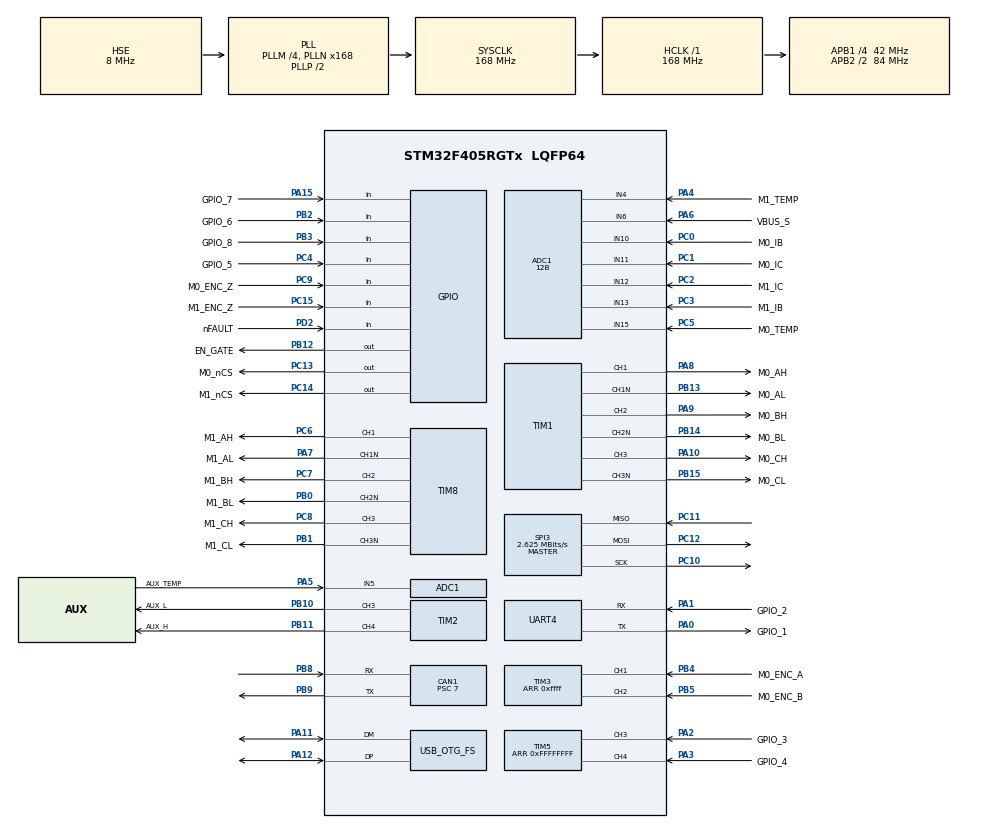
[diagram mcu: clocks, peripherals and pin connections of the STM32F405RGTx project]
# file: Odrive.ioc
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NVIC.CAN1_RX1_IRQn=true\:6\:0\:true\:false\:true\:true\:true\:true
PH0-OSC_IN.Signal=RCC_OSC_IN
SPI3.Direction=SPI_DIRECTION_2LINES
SPI3.VirtualType=VM_MASTER
ADC3.ExternalTrigInjecConv=ADC_EXTERNALTRIGINJECCONV_T1_TRGO
ADC3.ExternalTrigInjecConvEdge=ADC_EXTERNALTRIGINJECCONVEDGE_RISING
PC12.Signal=SPI3_MOSI
USB_DEVICE.PID_CDC_FS=0x0D32
PB14.GPIO_Label=M0_BL
PC6.GPIO_Label=M1_AH
Dma.SPI3_RX.2.Direction=DMA_PERIPH_TO_MEMORY
ADC2.InjectedOffset-1\#ChannelInjectedConversion=0
PA6.GPIO_Label=VBUS_S
PB6.GPIO_Label=M1_SCL
PB13.Signal=TIM1_CH1N
PC15-OSC32_OUT.GPIO_Label=M1_ENC_Z
TIM8.OffStateIDLEMode=TIM_OSSI_ENABLE
RCC.SYSCLKSource=RCC_SYSCLKSOURCE_PLLCLK
USB_OTG_FS.vbus_sensing_enable=DISABLE
ADC3.Rank-7\#ChannelRegularConversion=1
NVIC.TIM5_IRQn=true\:5\:0\:false\:false\:true\:true\:true\:true
NVIC.CAN1_TX_IRQn=true\:6\:0\:true\:false\:true\:true\:true\:true
RCC.APB2TimFreq_Value=84000000
PB6.Signal=I2C1_SCL
Dma.ADC1.0.Direction=DMA_PERIPH_TO_MEMORY
PC7.Signal=S_TIM8_CH2
ADC1.InjNumberOfConversion=1
PC3.Signal=ADCx_IN13
ADC3.ScanConvMode=DISABLE
ADC2.EOCSelection=ADC_EOC_SINGLE_CONV
PA1.GPIO_PuPd=GPIO_NOPULL
Dma.ADC1.0.MemDataAlignment=DMA_MDATAALIGN_HALFWORD
NVIC.TIM8_TRG_COM_TIM14_IRQn=true\:0\:0\:false\:false\:true\:false\:false\:true
PB2.Signal=GPIO_Input
ADC1.ScanConvMode=DISABLE
TIM2.OCMode_PWM-PWM\ Generation3\ CH3=TIM_OCMODE_PWM2
PC13-ANTI_TAMP.Signal=GPIO_Output
SH.ADCx_IN15.1=ADC2_IN15,IN15
SH.ADCx_IN15.0=ADC1_IN15,IN15
PB12.GPIO_Label=EN_GATE
ADC3.ExternalTrigConv=ADC_EXTERNALTRIGCONV_T8_TRGO
ADC3.InjectedConvMode=None
PC4.GPIO_Label=GPIO_5
USB_DEVICE.MANUFACTURER_STRING-CDC_FS=ODrive Robotics
PB14.Mode=PWM Generation2 CH2 CH2N
PB9.Stacked=true
PB1.GPIO_Label=M1_CL
Dma.ADC1.0.PeriphInc=DMA_PINC_DISABLE
TIM1.DeadTime=TIM_1_8_DEADTIME_CLOCKS
ADC3.ContinuousConvMode=DISABLE
TIM1.OCMode_PWM-PWM\ Generation1\ CH1\ CH1N=TIM_OCMODE_PWM2
ADC2.EnableAnalogWatchDog=false
PA8.Signal=S_TIM1_CH1
ADC1.InjectedConvMode=None
USB_DEVICE.VID-CDC_FS=0x1209
VP_SYS_VS_tim14.Mode=TIM14
VP_TIM1_VS_ClockSourceINT.Mode=Internal
ADC1.SamplingTime-0\#ChannelRegularConversion=ADC_SAMPLETIME_3CYCLES
CAN1.Prescaler=7
Mcu.Package=LQFP64
PB9.Signal=CAN1_TX
PB1.Signal=TIM8_CH3N
NVIC.TimeBase=TIM8_TRG_COM_TIM14_IRQn
SPI3.Mode=SPI_MODE_MASTER
NVIC.TimeBaseIP=TIM14
TIM1.OCMode_PWM-PWM\ Generation3\ CH3\ CH3N=TIM_OCMODE_PWM2
PA10.Signal=S_TIM1_CH3
PC11.Mode=Full_Duplex_Master
Dma.SPI3_RX.2.PeriphInc=DMA_PINC_DISABLE
ADC1.Rank-1\#ChannelInjectedConversion=1
ADC3.DMAContinuousRequests=DISABLE
RCC.APB2CLKDivider=RCC_HCLK_DIV2
ADC3.ExternalTrigConvEdge=ADC_EXTERNALTRIGCONVEDGE_RISING
RCC.APB1TimFreq_Value=84000000
TIM5.ICFilter_CH4=15
TIM5.ICFilter_CH3=15
Dma.ADC1.0.FIFOMode=DMA_FIFOMODE_DISABLE
TIM1.OCMode_PWM-PWM\ Generation2\ CH2\ CH2N=TIM_OCMODE_PWM2
TIM1.Period=TIM_1_8_PERIOD_CLOCKS
PB13.Mode=PWM Generation1 CH1 CH1N
ADC2.ExternalTrigInjecConvEdge=ADC_EXTERNALTRIGINJECCONVEDGE_RISING
CAN1.CalculateTimeBit=500
TIM2.OCMode_PWM-PWM\ Generation4\ CH4=TIM_OCMODE_PWM2
PA4.GPIO_Label=M1_TEMP
ADC1.EOCSelection=ADC_EOC_SINGLE_CONV
ADC2.ScanConvMode=DISABLE
CAN1.CalculateTimeQuantum=166.66666666666669
NVIC.UART4_IRQn=true\:5\:0\:false\:false\:true\:true\:true\:true
SH.S_TIM8_CH3.0=TIM8_CH3,PWM Generation3 CH3 CH3N
Dma.SPI3_TX.1.MemInc=DMA_MINC_ENABLE
TIM8.OffStateRunMode=TIM_OSSR_ENABLE
Dma.ADC1.0.Instance=DMA2_Stream0
FREERTOS.Tasks01=defaultTask,0,256,StartDefaultTask,Default,NULL,Dynamic,NULL,NULL
ADC1.Rank-0\#ChannelRegularConversion=1
PD2.GPIO_PuPd=GPIO_PULLUP
TIM5.Channel-Input_Capture4_from_TI4=TIM_CHANNEL_4
SH.ADCx_IN6.0=ADC1_IN6,IN6
PC13-ANTI_TAMP.GPIO_Label=M0_nCS
SH.ADCx_IN6.1=ADC2_IN6,IN6
TIM1.CounterMode=TIM_COUNTERMODE_CENTERALIGNED3
PA9.GPIO_Label=M0_BH
TIM8.Channel-Output\ Compare4\ No\ Output=TIM_CHANNEL_4
FREERTOS.INCLUDE_vTaskDelayUntil=1
FREERTOS.configCHECK_FOR_STACK_OVERFLOW=1
PC6.Signal=S_TIM8_CH1
PC2.Signal=ADCx_IN12
PB11.GPIO_Label=AUX_H
TIM1.Channel-PWM\ Generation1\ CH1\ CH1N=TIM_CHANNEL_1
ADC2.Channel-1\#ChannelInjectedConversion=ADC_CHANNEL_10
Dma.SPI3_TX.1.Priority=DMA_PRIORITY_MEDIUM
TIM2.OCPolarity_3=TIM_OCPOLARITY_LOW
ADC1.ExternalTrigConvEdge=ADC_EXTERNALTRIGCONVEDGE_NONE
PC0.Signal=ADCx_IN10
RCC.APB1CLKDivider=RCC_HCLK_DIV4
UART4.VirtualMode=Asynchronous
PC14-OSC32_IN.Signal=GPIO_Output
SH.S_TIM8_CH2.0=TIM8_CH2,PWM Generation2 CH2 CH2N
PC13-ANTI_TAMP.PinState=GPIO_PIN_SET
ADC3.Resolution=ADC_RESOLUTION_12B
PA0-WKUP.GPIO_Label=GPIO_1
PA0-WKUP.Signal=SharedStack_PA0
TIM1.Channel-PWM\ Generation2\ CH2\ CH2N=TIM_CHANNEL_2
PA8.GPIO_Label=M0_AH
ADC2.ContinuousConvMode=DISABLE
TIM3.IC2Filter=4
USB_DEVICE.PRODUCT_STRING_CDC_FS=ODrive v3.3
USB_DEVICE.APP_TX_DATA_SIZE-CDC_FS=64
Dma.ADC1.0.Priority=DMA_PRIORITY_LOW
PA9.Signal=S_TIM1_CH2
Dma.SPI3_TX.1.MemDataAlignment=DMA_MDATAALIGN_HALFWORD
TIM1.Channel-PWM\ Generation3\ CH3\ CH3N=TIM_CHANNEL_3
ADC1.Channel-1\#ChannelInjectedConversion=ADC_CHANNEL_6
ADC3.NbrOfConversion=1
SPI3.FirstBit=SPI_FIRSTBIT_MSB
PB10.Signal=S_TIM2_CH3
PB14.Signal=TIM1_CH2N
PA5.Signal=ADCx_IN5
TIM3.IC1Filter=4
SH.S_TIM8_CH1.0=TIM8_CH1,PWM Generation1 CH1 CH1N
PC12.Mode=Full_Duplex_Master
ADC3.SamplingTime-8\#ChannelInjectedConversion=ADC_SAMPLETIME_3CYCLES
TIM13.Period=(2 * TIM_1_8_PERIOD_CLOCKS * (TIM_1_8_RCR+1)) * (TIM_APB1_CLOCK_HZ / TIM_1_8_CLOCK_HZ)
TIM1.TIM_MasterOutputTrigger=TIM_TRGO_UPDATE
VP_TIM13_VS_ClockSourceINT.Mode=Enable_Timer
PB4.GPIO_Label=M0_ENC_A
PB15.GPIO_Label=M0_CL
ADC1.InjectedOffset-1\#ChannelInjectedConversion=0
SH.ADCx_IN4.1=ADC2_IN4,IN4
PA1.GPIO_Label=GPIO_2
SH.ADCx_IN4.0=ADC1_IN4,IN4
ADC1.DMAContinuousRequests=DISABLE
TIM2.Period=TIM_APB1_PERIOD_CLOCKS
PA13.Mode=Serial_Wire
TIM8.RepetitionCounter=TIM_1_8_RCR
ADC2.Resolution=ADC_RESOLUTION_12B
ADC1.ExternalTrigConv=ADC_SOFTWARE_START
TIM8.Period=TIM_1_8_PERIOD_CLOCKS
PC7.GPIO_Label=M1_BH
RCC.APB2TimCLKDivider=1
Dma.SPI3_TX.1.PeriphInc=DMA_PINC_DISABLE
PA4.Signal=ADCx_IN4
PB5.Signal=S_TIM3_CH2
ADC1.master=1
PA5.GPIO_Label=AUX_TEMP
ADC2.NbrOfConversionFlag=1
TIM8.TIM_MasterOutputTrigger=TIM_TRGO_UPDATE
PA11.Signal=USB_OTG_FS_DM
ProjectManager.HeapSize=0x3C00
PB1.Mode=PWM Generation3 CH3 CH3N
ADC3.EOCSelection=ADC_EOC_SINGLE_CONV
NVIC.TIM1_UP_TIM10_IRQn=true\:0\:0\:false\:false\:false\:false\:true\:true
NVIC.TIM8_UP_TIM13_IRQn=true\:0\:0\:false\:false\:false\:false\:true\:true
SH.ADCx_IN5.0=ADC1_IN5,IN5
SH.ADCx_IN5.1=ADC2_IN5,IN5
NVIC.PriorityGroup=NVIC_PRIORITYGROUP_4
PB8.Mode=Master
PC3.GPIO_Label=M1_IB
PA0-WKUP.GPIO_PuPd=GPIO_PULLDOWN
TIM2.Pulse-PWM\ Generation4\ CH4=TIM_APB1_PERIOD_CLOCKS+1
ADC3.Rank-8\#ChannelInjectedConversion=1
PD2.Signal=GPIO_Input
PB0.Signal=TIM8_CH2N
PC1.Signal=ADCx_IN11
PD2.GPIO_Label=nFAULT
NVIC.CAN1_RX0_IRQn=true\:6\:0\:true\:false\:true\:true\:true\:true
TIM8.CounterMode=TIM_COUNTERMODE_CENTERALIGNED3
ADC3.EnableAnalogWatchDog=false
Mcu.Family=STM32F4
ADC2.ExternalTrigConv=ADC_EXTERNALTRIGCONV_T8_TRGO
USB_DEVICE.CLASS_NAME_FS=CDC
RCC.CortexFreq_Value=168000000
CAN1.AutoWakeUp=ENABLE
ADC1.ContinuousConvMode=DISABLE
ADC2.Channel-0\#ChannelRegularConversion=ADC_CHANNEL_13
TIM1.RepetitionCounter=TIM_1_8_RCR
ADC3.SamplingTime-7\#ChannelRegularConversion=ADC_SAMPLETIME_3CYCLES
ADC2.InjectedConvMode=None
Dma.SPI3_RX.2.Instance=DMA1_Stream0
PC10.Signal=SPI3_SCK
TIM3.EncoderMode=TIM_ENCODERMODE_TI12
PC0.GPIO_Label=M0_IB
PA11.Mode=Device_Only
PB0.GPIO_Label=M1_BL
USB_DEVICE.VirtualMode-CDC_FS=Cdc
PB13.GPIO_Label=M0_AL
PB11.Signal=S_TIM2_CH4
PB15.Signal=TIM1_CH3N
ADC2.DiscontinuousConvMode=DISABLE
Dma.SPI3_RX.2.PeriphDataAlignment=DMA_PDATAALIGN_HALFWORD
ProjectManager.StackSize=0x800
NVIC.ADC_IRQn=true\:5\:0\:false\:false\:true\:true\:true\:true
PA15.GPIO_Label=GPIO_7
PA12.Signal=USB_OTG_FS_DP
Mcu.UserConstants=TIM_1_8_CLOCK_HZ,168000000;TIM_1_8_PERIOD_CLOCKS,3500;TIM_1_8_DEADTIME_CLOCKS,20;TIM_APB1_CLOCK_HZ,84000000;TIM_APB1_PERIOD_CLOCKS,4096;TIM_APB1_DEADTIME_CLOCKS,40;TIM_1_8_RCR,2
ADC2.DMAContinuousRequests=DISABLE
ADC2.Rank-1\#ChannelInjectedConversion=1
TIM8.Channel-PWM\ Generation2\ CH2\ CH2N=TIM_CHANNEL_2
RCC.HCLKFreq_Value=168000000
ADC1.Resolution=ADC_RESOLUTION_12B
USB_DEVICE.SERIALNUMBER_STRING_CDC_FS=000000000001
TIM3.Period=0xffff
SH.S_TIM5_CH3.0=TIM5_CH3,Input_Capture3_from_TI3
ADC3.InjectedOffset-8\#ChannelInjectedConversion=0
NVIC.DMA2_Stream0_IRQn=true\:5\:0\:false\:false\:false\:true\:false\:true
NVIC.CAN1_SCE_IRQn=true\:6\:0\:true\:false\:true\:true\:true\:true
PB8.Stacked=true
RCC.AHBFreq_Value=168000000
PH0-OSC_IN.Mode=HSE-External-Oscillator
SPI3.DataSize=SPI_DATASIZE_16BIT
TIM8.Channel-PWM\ Generation1\ CH1\ CH1N=TIM_CHANNEL_1
ADC1.Channel-0\#ChannelRegularConversion=ADC_CHANNEL_6
ADC1.ExternalTrigInjecConv=ADC_EXTERNALTRIGINJECCONV_T1_TRGO
RCC.HSE_VALUE=8000000
ADC3.InjNumberOfConversion=1
PA14.Mode=Serial_Wire
PA0-WKUP.Stacked=true
PA10.GPIO_Label=M0_CH
ADC3.DataAlign=ADC_DATAALIGN_RIGHT
PB7.Signal=I2C1_SDA
SH.S_TIM3_CH1.0=TIM3_CH1,Encoder_Interface
PA1.Stacked=true
FREERTOS.configTOTAL_HEAP_SIZE=65536
Dma.SPI3_RX.2.FIFOMode=DMA_FIFOMODE_DISABLE
SH.SharedStack_PA1.0=GPIO_Input+0
VP_FREERTOS_VS_ENABLE.Mode=Enabled
USB_DEVICE.APP_RX_DATA_SIZE-CDC_FS=64
SH.SharedStack_PA1.1=UART4_RX,Asynchronous
PH1-OSC_OUT.Mode=HSE-External-Oscillator
PB7.GPIO_Label=M1_SDA
TIM8.OCMode_PWM-PWM\ Generation1\ CH1\ CH1N=TIM_OCMODE_PWM2
PA6.Signal=ADCx_IN6
TIM8.Channel-PWM\ Generation3\ CH3\ CH3N=TIM_CHANNEL_3
PC14-OSC32_IN.PinState=GPIO_PIN_SET
ADC1.SamplingTime-1\#ChannelInjectedConversion=ADC_SAMPLETIME_3CYCLES
NVIC.OTG_FS_IRQn=true\:5\:0\:false\:false\:true\:true\:true\:true
PA2.GPIO_Label=GPIO_3
USB_OTG_FS.VirtualMode=Device_Only
PA15.Signal=GPIO_Input
TIM8.OCMode_PWM-PWM\ Generation3\ CH3\ CH3N=TIM_OCMODE_PWM2
ADC2.SamplingTime-0\#ChannelRegularConversion=ADC_SAMPLETIME_3CYCLES
NVIC.SPI3_IRQn=true\:5\:0\:false\:false\:true\:true\:true\:true
ADC3.ClockPrescaler=ADC_CLOCK_SYNC_PCLK_DIV4
Dma.SPI3_TX.1.Direction=DMA_MEMORY_TO_PERIPH
PB5.GPIO_Label=M0_ENC_B
Dma.SPI3_RX.2.Priority=DMA_PRIORITY_MEDIUM
ADC2.NbrOfConversion=1
Dma.Request2=SPI3_RX
Dma.Request1=SPI3_TX
NVIC.DMA1_Stream0_IRQn=true\:5\:0\:false\:false\:true\:true\:false\:true
PC14-OSC32_IN.GPIO_Label=M1_nCS
PC5.Signal=ADCx_IN15
ADC2.Rank-0\#ChannelRegularConversion=1
TIM8.OCMode_PWM-PWM\ Generation2\ CH2\ CH2N=TIM_OCMODE_PWM2
Dma.Request0=ADC1
PC2.GPIO_Label=M1_IC
SH.SharedStack_PA0.1=UART4_TX,Asynchronous
SH.SharedStack_PA0.0=GPIO_EXTI0+0
PB4.Signal=S_TIM3_CH1
PA3.Signal=S_TIM5_CH4
ADC1.ExternalTrigInjecConvEdge=ADC_EXTERNALTRIGINJECCONVEDGE_RISING
PB3.GPIO_Label=GPIO_8
ADC3.Channel-7\#ChannelRegularConversion=ADC_CHANNEL_12
SH.ADCx_IN13.2=ADC3_IN13,IN13
ADC2.ClockPrescaler=ADC_CLOCK_SYNC_PCLK_DIV4
SH.ADCx_IN13.1=ADC2_IN13,IN13
ADC3.DiscontinuousConvMode=DISABLE
TIM2.Channel-PWM\ Generation4\ CH4=TIM_CHANNEL_4
SH.ADCx_IN13.0=ADC1_IN13,IN13
ADC2.ExternalTrigInjecConv=ADC_EXTERNALTRIGINJECCONV_T1_TRGO
TIM1.OffStateIDLEMode=TIM_OSSI_ENABLE
PA7.Mode=PWM Generation1 CH1 CH1N
TIM2.CounterMode=TIM_COUNTERMODE_CENTERALIGNED3
PC9.GPIO_Label=M0_ENC_Z
USB_DEVICE.VirtualModeFS=Cdc_FS
ADC3.Channel-8\#ChannelInjectedConversion=ADC_CHANNEL_11
PC11.Signal=SPI3_MISO
PC8.Signal=S_TIM8_CH3
PC4.Signal=GPIO_Input
PC10.Mode=Full_Duplex_Master
ADC1.DiscontinuousConvMode=DISABLE
Dma.SPI3_TX.1.FIFOMode=DMA_FIFOMODE_DISABLE
Dma.SPI3_TX.1.Instance=DMA1_Stream5
TIM5.ICPolarity_CH4=TIM_INPUTCHANNELPOLARITY_BOTHEDGE
TIM5.ICPolarity_CH3=TIM_INPUTCHANNELPOLARITY_BOTHEDGE
FREERTOS.INCLUDE_uxTaskGetStackHighWaterMark=1
SH.ADCx_IN12.2=ADC3_IN12,IN12
PC8.GPIO_Label=M1_CH
Dma.SPI3_TX.1.PeriphDataAlignment=DMA_PDATAALIGN_HALFWORD
PA13.Signal=SYS_JTMS-SWDIO
FREERTOS.configUSE_IDLE_HOOK=1
SH.ADCx_IN12.1=ADC2_IN12,IN12
Dma.ADC1.0.PeriphDataAlignment=DMA_PDATAALIGN_HALFWORD
SH.ADCx_IN12.0=ADC1_IN12,IN12
SH.S_TIM1_CH1.0=TIM1_CH1,PWM Generation1 CH1 CH1N
CAN1.BS2=CAN_BS2_5TQ
CAN1.BS1=CAN_BS1_6TQ
Dma.SPI3_TX.1.Mode=DMA_NORMAL
ProjectManager.TargetToolchain=Makefile
PB10.GPIO_Label=AUX_L
NVIC.DMA1_Stream5_IRQn=true\:5\:0\:false\:false\:true\:true\:false\:true
Dma.ADC1.0.Mode=DMA_CIRCULAR
VP_USB_DEVICE_VS_USB_DEVICE_CDC_FS.Mode=CDC_FS
PB9.Mode=Master
RCC.LSE_VALUE=32768
PC15-OSC32_OUT.Signal=GPIO_Input
PA1.Signal=SharedStack_PA1
TIM3.IC2Polarity=TIM_ICPOLARITY_RISING
SH.S_TIM3_CH2.0=TIM3_CH2,Encoder_Interface
ADC2.SamplingTime-1\#ChannelInjectedConversion=ADC_SAMPLETIME_3CYCLES
PB0.Mode=PWM Generation2 CH2 CH2N
TIM8.DeadTime=TIM_1_8_DEADTIME_CLOCKS
board=Odrive
SPI3.CLKPhase=SPI_PHASE_2EDGE
RCC.VCOOutputFreq_Value=336000000
TIM1.OCNPolarity_1=TIM_OCNPOLARITY_HIGH
PB15.Mode=PWM Generation3 CH3 CH3N
VP_TIM1_VS_no_output4.Mode=Output Compare4 No Output
ADC1.EnableAnalogWatchDog=false
ADC2.DataAlign=ADC_DATAALIGN_RIGHT
RCC.APB2Freq_Value=84000000
SH.ADCx_IN11.2=ADC3_IN11,IN11
SPI3.CalculateBaudRate=2.625 MBits/s
TIM1.OCNPolarity_3=TIM_OCNPOLARITY_HIGH
SH.ADCx_IN11.1=ADC2_IN11,IN11
TIM1.OCNPolarity_2=TIM_OCNPOLARITY_HIGH
SH.ADCx_IN11.0=ADC1_IN11,IN11
SH.S_TIM1_CH2.0=TIM1_CH2,PWM Generation2 CH2 CH2N
SH.S_TIM2_CH3.0=TIM2_CH3,PWM Generation3 CH3
SPI3.BaudRatePrescaler=SPI_BAUDRATEPRESCALER_16
PC1.GPIO_Label=M0_IC
TIM2.Channel-PWM\ Generation3\ CH3=TIM_CHANNEL_3
PH1-OSC_OUT.Signal=RCC_OSC_OUT
CAN1.TimeSeg1=CAN_BS1_6TQ
SH.S_TIM5_CH4.0=TIM5_CH4,Input_Capture4_from_TI4
CAN1.TimeSeg2=CAN_BS2_5TQ
TIM1.OffStateRunMode=TIM_OSSR_ENABLE
ADC1.NbrOfConversion=1
Dma.SPI3_RX.2.Mode=DMA_NORMAL
Mcu.Name=STM32F405RGTx
PA2.Signal=S_TIM5_CH3
RCC.48MHZClocksFreq_Value=48000000
PB3.Signal=GPIO_Input
RCC.SYSCLKFreq_VALUE=168000000
PA7.GPIO_Label=M1_AL
PA12.Mode=Device_Only
PC5.GPIO_Label=M0_TEMP
Dma.SPI3_RX.2.MemInc=DMA_MINC_ENABLE
TIM3.IC1Polarity=TIM_ICPOLARITY_RISING
SH.ADCx_IN10.2=ADC3_IN10,IN10
SH.ADCx_IN10.1=ADC2_IN10,IN10
PA14.Signal=SYS_JTCK-SWCLK
Dma.ADC1.0.MemInc=DMA_MINC_ENABLE
SH.ADCx_IN10.0=ADC1_IN10,IN10
PB2.GPIO_Label=GPIO_6
SH.S_TIM2_CH4.0=TIM2_CH4,PWM Generation4 CH4
SH.S_TIM1_CH3.0=TIM1_CH3,PWM Generation3 CH3 CH3N
TIM1.Channel-Output\ Compare4\ No\ Output=TIM_CHANNEL_4
RCC.HSI_VALUE=16000000
ADC2.ExternalTrigConvEdge=ADC_EXTERNALTRIGCONVEDGE_RISING
RCC.PLLQ=7
ADC1.NbrOfConversionFlag=1
RCC.PLLM=4
RCC.PLLN=168
PB8.Signal=CAN1_RX
TIM5.Period=0xFFFFFFFF
PC9.Signal=GPIO_Input
Dma.SPI3_RX.2.MemDataAlignment=DMA_MDATAALIGN_HALFWORD
ADC1.DataAlign=ADC_DATAALIGN_RIGHT
RCC.APB1Freq_Value=42000000
ADC3.NbrOfConversionFlag=1
ADC1.ClockPrescaler=ADC_CLOCK_SYNC_PCLK_DIV4
ADC2.InjNumberOfConversion=1
PB12.Signal=GPIO_Output
TIM5.Channel-Input_Capture3_from_TI3=TIM_CHANNEL_3
PA3.GPIO_Label=GPIO_4
PA7.Signal=TIM8_CH1N

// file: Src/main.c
/**
  ******************************************************************************
  * @file           : main.c
  * @brief          : Main program body
  ******************************************************************************
  * This notice applies to any and all portions of this file
  * that are not between comment pairs USER CODE BEGIN and
  * USER CODE END. Other portions of this file, whether
  * inserted by the user or by software development tools
  * are owned by their respective copyright owners.
  *
  * Copyright (c) 2020 STMicroelectronics International N.V.
  * All rights reserved.
  *
  * Redistribution and use in source and binary forms, with or without
  * modification, are permitted, provided that the following conditions are met:
  *
  * 1. Redistribution of source code must retain the above copyright notice,
  *    this list of conditions and the following disclaimer.
  * 2. Redistributions in binary form must reproduce the above copyright notice,
  *    this list of conditions and the following disclaimer in the documentation
  *    and/or other materials provided with the distribution.
  * 3. Neither the name of STMicroelectronics nor the names of other
  *    contributors to this software may be used to endorse or promote products
  *    derived from this software without specific written permission.
  * 4. This software, including modifications and/or derivative works of this
  *    software, must execute solely and exclusively on microcontroller or
  *    microprocessor devices manufactured by or for STMicroelectronics.
  * 5. Redistribution and use of this software other than as permitted under
  *    this license is void and will automatically terminate your rights under
  *    this license.
  *
  * THIS SOFTWARE IS PROVIDED BY STMICROELECTRONICS AND CONTRIBUTORS "AS IS"
  * AND ANY EXPRESS, IMPLIED OR STATUTORY WARRANTIES, INCLUDING, BUT NOT
  * LIMITED TO, THE IMPLIED WARRANTIES OF MERCHANTABILITY, FITNESS FOR A
  * PARTICULAR PURPOSE AND NON-INFRINGEMENT OF THIRD PARTY INTELLECTUAL PROPERTY
  * RIGHTS ARE DISCLAIMED TO THE FULLEST EXTENT PERMITTED BY LAW. IN NO EVENT
  * SHALL STMICROELECTRONICS OR CONTRIBUTORS BE LIABLE FOR ANY DIRECT, INDIRECT,
  * INCIDENTAL, SPECIAL, EXEMPLARY, OR CONSEQUENTIAL DAMAGES (INCLUDING, BUT NOT
  * LIMITED TO, PROCUREMENT OF SUBSTITUTE GOODS OR SERVICES; LOSS OF USE, DATA,
  * OR PROFITS; OR BUSINESS INTERRUPTION) HOWEVER CAUSED AND ON ANY THEORY OF
  * LIABILITY, WHETHER IN CONTRACT, STRICT LIABILITY, OR TORT (INCLUDING
  * NEGLIGENCE OR OTHERWISE) ARISING IN ANY WAY OUT OF THE USE OF THIS SOFTWARE,
  * EVEN IF ADVISED OF THE POSSIBILITY OF SUCH DAMAGE.
  *
  ******************************************************************************
  */
#include "main.h"
#include "stm32f4xx_hal.h"
#include "cmsis_os.h"
#include "adc.h"
#include "can.h"
#include "dma.h"
#include "spi.h"
#include "tim.h"
#include "usart.h"
#include "usb_device.h"
#include "gpio.h"

/* USER CODE BEGIN PV */
/* Private variables ---------------------------------------------------------*/

/* USER CODE END PV */

void SystemClock_Config(void);
void MX_FREERTOS_Init(void);

/* USER CODE BEGIN PFP */
/* Private function prototypes -----------------------------------------------*/

/* USER CODE END PFP */

int main(void)
{

  /* MCU Configuration----------------------------------------------------------*/

  /* Reset of all peripherals, Initializes the Flash interface and the Systick. */
  HAL_Init();

  /* Configure the system clock */
  SystemClock_Config();

  /* Initialize all configured peripherals */
  MX_GPIO_Init();
  MX_DMA_Init();
  MX_ADC1_Init();
  MX_ADC2_Init();
  MX_CAN1_Init();
  MX_TIM1_Init();
  MX_TIM8_Init();
  MX_TIM3_Init();
  MX_SPI3_Init();
  MX_ADC3_Init();
  MX_TIM2_Init();
  MX_UART4_Init();
  MX_TIM5_Init();
  MX_TIM13_Init();

  /* Call init function for freertos objects (in freertos.c) */
  MX_FREERTOS_Init();

  /* Start scheduler */
  osKernelStart();

  /* We should never get here as control is now taken by the scheduler */

  /* Infinite loop */
  while (1)
  {

  }

}

void SystemClock_Config(void)
{

  RCC_OscInitTypeDef RCC_OscInitStruct;
  RCC_ClkInitTypeDef RCC_ClkInitStruct;

    /**Configure the main internal regulator output voltage
    */
  __HAL_RCC_PWR_CLK_ENABLE();

  __HAL_PWR_VOLTAGESCALING_CONFIG(PWR_REGULATOR_VOLTAGE_SCALE1);

    /**Initializes the CPU, AHB and APB busses clocks
    */
  RCC_OscInitStruct.OscillatorType = RCC_OSCILLATORTYPE_LSI|RCC_OSCILLATORTYPE_HSE;
  RCC_OscInitStruct.HSEState = RCC_HSE_ON;
  RCC_OscInitStruct.LSIState = RCC_LSI_ON;
  RCC_OscInitStruct.PLL.PLLState = RCC_PLL_ON;
  RCC_OscInitStruct.PLL.PLLSource = RCC_PLLSOURCE_HSE;
  RCC_OscInitStruct.PLL.PLLM = 4;
  RCC_OscInitStruct.PLL.PLLN = 168;
  RCC_OscInitStruct.PLL.PLLP = RCC_PLLP_DIV2;
  RCC_OscInitStruct.PLL.PLLQ = 7;
  if (HAL_RCC_OscConfig(&RCC_OscInitStruct) != HAL_OK)
  {
    _Error_Handler(__FILE__, __LINE__);
  }

    /**Initializes the CPU, AHB and APB busses clocks
    */
  RCC_ClkInitStruct.ClockType = RCC_CLOCKTYPE_HCLK|RCC_CLOCKTYPE_SYSCLK
                              |RCC_CLOCKTYPE_PCLK1|RCC_CLOCKTYPE_PCLK2;
  RCC_ClkInitStruct.SYSCLKSource = RCC_SYSCLKSOURCE_PLLCLK;
  RCC_ClkInitStruct.AHBCLKDivider = RCC_SYSCLK_DIV1;
  RCC_ClkInitStruct.APB1CLKDivider = RCC_HCLK_DIV4;
  RCC_ClkInitStruct.APB2CLKDivider = RCC_HCLK_DIV2;

  if (HAL_RCC_ClockConfig(&RCC_ClkInitStruct, FLASH_LATENCY_5) != HAL_OK)
  {
    _Error_Handler(__FILE__, __LINE__);
  }

    /**Configure the Systick interrupt time
    */
  HAL_SYSTICK_Config(HAL_RCC_GetHCLKFreq()/1000);

    /**Configure the Systick
    */
  HAL_SYSTICK_CLKSourceConfig(SYSTICK_CLKSOURCE_HCLK);

  /* SysTick_IRQn interrupt configuration */
  HAL_NVIC_SetPriority(SysTick_IRQn, 15, 0);
}

void HAL_TIM_PeriodElapsedCallback(TIM_HandleTypeDef *htim)
{
  if (htim->Instance == TIM14) {
    HAL_IncTick();
  }
}

void _Error_Handler(char *file, int line)
{
  /* USER CODE BEGIN Error_Handler_Debug */
  /* User can add his own implementation to report the HAL error return state */
  while(1) // TODO: do something more useful
  {
  }
  /* USER CODE END Error_Handler_Debug */
}

/************************ (C) COPYRIGHT STMicroelectronics *****END OF FILE****/

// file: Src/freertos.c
/* USER CODE BEGIN Header */
/**
  ******************************************************************************
  * File Name          : freertos.c
  * Description        : Code for freertos applications
  ******************************************************************************
  * This notice applies to any and all portions of this file
  * that are not between comment pairs USER CODE BEGIN and
  * USER CODE END. Other portions of this file, whether
  * inserted by the user or by software development tools
  * are owned by their respective copyright owners.
  *
  * Copyright (c) 2018 STMicroelectronics International N.V.
  * All rights reserved.
  *
  * Redistribution and use in source and binary forms, with or without
  * modification, are permitted, provided that the following conditions are met:
  *
  * 1. Redistribution of source code must retain the above copyright notice,
  *    this list of conditions and the following disclaimer.
  * 2. Redistributions in binary form must reproduce the above copyright notice,
  *    this list of conditions and the following disclaimer in the documentation
  *    and/or other materials provided with the distribution.
  * 3. Neither the name of STMicroelectronics nor the names of other
  *    contributors to this software may be used to endorse or promote products
  *    derived from this software without specific written permission.
  * 4. This software, including modifications and/or derivative works of this
  *    software, must execute solely and exclusively on microcontroller or
  *    microprocessor devices manufactured by or for STMicroelectronics.
  * 5. Redistribution and use of this software other than as permitted under
  *    this license is void and will automatically terminate your rights under
  *    this license.
  *
  * THIS SOFTWARE IS PROVIDED BY STMICROELECTRONICS AND CONTRIBUTORS "AS IS"
  * AND ANY EXPRESS, IMPLIED OR STATUTORY WARRANTIES, INCLUDING, BUT NOT
  * LIMITED TO, THE IMPLIED WARRANTIES OF MERCHANTABILITY, FITNESS FOR A
  * PARTICULAR PURPOSE AND NON-INFRINGEMENT OF THIRD PARTY INTELLECTUAL PROPERTY
  * RIGHTS ARE DISCLAIMED TO THE FULLEST EXTENT PERMITTED BY LAW. IN NO EVENT
  * SHALL STMICROELECTRONICS OR CONTRIBUTORS BE LIABLE FOR ANY DIRECT, INDIRECT,
  * INCIDENTAL, SPECIAL, EXEMPLARY, OR CONSEQUENTIAL DAMAGES (INCLUDING, BUT NOT
  * LIMITED TO, PROCUREMENT OF SUBSTITUTE GOODS OR SERVICES; LOSS OF USE, DATA,
  * OR PROFITS; OR BUSINESS INTERRUPTION) HOWEVER CAUSED AND ON ANY THEORY OF
  * LIABILITY, WHETHER IN CONTRACT, STRICT LIABILITY, OR TORT (INCLUDING
  * NEGLIGENCE OR OTHERWISE) ARISING IN ANY WAY OUT OF THE USE OF THIS SOFTWARE,
  * EVEN IF ADVISED OF THE POSSIBILITY OF SUCH DAMAGE.
  *
  ******************************************************************************
  */
/* USER CODE END Header */

#include "FreeRTOS.h"
#include "task.h"
#include "main.h"
#include "cmsis_os.h"

osThreadId defaultTaskHandle;

void StartDefaultTask(void const * argument);

extern void MX_USB_DEVICE_Init(void);
void MX_FREERTOS_Init(void); /* (MISRA C 2004 rule 8.1) */

/* Hook prototypes */
void vApplicationIdleHook(void);
void vApplicationStackOverflowHook(xTaskHandle xTask, signed char *pcTaskName);

/* USER CODE BEGIN 2 */
__weak void vApplicationIdleHook( void )
{
   /* vApplicationIdleHook() will only be called if configUSE_IDLE_HOOK is set
   to 1 in FreeRTOSConfig.h. It will be called on each iteration of the idle
   task. It is essential that code added to this hook function never attempts
   to block in any way (for example, call xQueueReceive() with a block time
   specified, or call vTaskDelay()). If the application makes use of the
   vTaskDelete() API function (as this demo application does) then it is also
   important that vApplicationIdleHook() is permitted to return to its calling
   function, because it is the responsibility of the idle task to clean up
   memory allocated by the kernel to any task that has since been deleted. */
}
/* USER CODE END 2 */

/* USER CODE BEGIN 4 */
__weak void vApplicationStackOverflowHook(xTaskHandle xTask, signed char *pcTaskName)
{
   /* Run time stack overflow checking is performed if
   configCHECK_FOR_STACK_OVERFLOW is defined to 1 or 2. This hook function is
   called if a stack overflow is detected. */
}
/* USER CODE END 4 */

void MX_FREERTOS_Init(void) {

  /* Create the thread(s) */
  /* definition and creation of defaultTask */
  osThreadDef(defaultTask, StartDefaultTask, osPriorityNormal, 0, 256);
  defaultTaskHandle = osThreadCreate(osThread(defaultTask), NULL);

}

void StartDefaultTask(void const * argument)
{
  /* init code for USB_DEVICE */
  MX_USB_DEVICE_Init();

}

/************************ (C) COPYRIGHT STMicroelectronics *****END OF FILE****/
